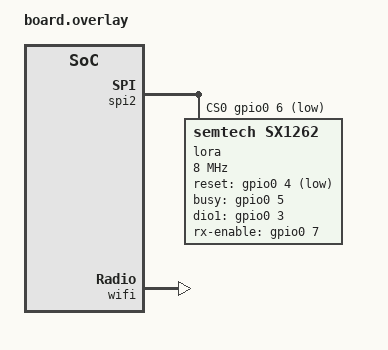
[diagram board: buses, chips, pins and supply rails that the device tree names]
/*
 * SPDX-License-Identifier: MIT
 * XIAO ESP32-C3 + SX1262 LoRa
 *
 * Pin mapping (from Arduino MeshCore variants/xiao_c3):
 * - D4 (GPIO6)  = NSS     - D8  (GPIO8)  = SPI SCK
 * - D1 (GPIO3)  = DIO1    - D9  (GPIO9)  = SPI MISO
 * - D3 (GPIO5)  = BUSY    - D10 (GPIO10) = SPI MOSI
 * - D2 (GPIO4)  = RESET
 * - D5 (GPIO7)  = RXEN
 * - D0 (GPIO2)  = VBAT (optional)
 *
 * Console: USB-Serial/JTAG (usb_serial)
 */

#include <zephyr/dt-bindings/lora/sx126x.h>

/ {
	aliases {
		lora0 = &lora;
	};

	chosen {
		zephyr,console = &usb_serial;
		zephyr,shell-uart = &usb_serial;
	};
};

/* SX1262 on SPI2 (XIAO SPI bus — SCK/MISO/MOSI already in pinctrl) */
&spi2 {
	cs-gpios = <&gpio0 6 GPIO_ACTIVE_LOW>;  /* D4 = GPIO6 NSS */

	lora: lora@0 {
		compatible = "semtech,sx1262";
		reg = <0>;
		spi-max-frequency = <8000000>;

		/* LoRa control pins */
		reset-gpios = <&gpio0 4 GPIO_ACTIVE_LOW>;   /* D2 = GPIO4 */
		busy-gpios = <&gpio0 5 GPIO_ACTIVE_HIGH>;   /* D3 = GPIO5 */
		dio1-gpios = <&gpio0 3 (GPIO_PULL_DOWN | GPIO_ACTIVE_HIGH)>;  /* D1 = GPIO3 */

		/* RF switch: RXEN for RX, DIO2 drives TX enable */
		rx-enable-gpios = <&gpio0 7 GPIO_ACTIVE_HIGH>;  /* D5 = GPIO7 RXEN */
		dio2-tx-enable;

		/* TCXO 1.8V via DIO3 */
		dio3-tcxo-voltage = <SX126X_DIO3_TCXO_1V8>;
		tcxo-power-startup-delay-ms = <10>;

		/* RX boosted mode for better sensitivity */
		rx-boosted;
	};
};

/*
 * Flash partitions live in partitions.overlay (this dir) so the identical map
 * is fed to both the app and the MCUboot image — see that file and
 * sysbuild/CMakeLists.txt.
 */

/* LittleFS auto-mount — standard /lfs mount point */
#include "../../common/filesystem.dtsi"

/* WiFi — required for OTA firmware updates */
&wifi {
	status = "okay";
};
